# APM32F445 register map
File version: 1.0
CPU: CM4 r0p1, little endian, MPU, FPU, 4 interrupt priority bits
Registers are 32-bit, read-write, reset 0x0 unless marked. A register's access mark holds for its fields unless they carry their own. Offsets are from the block's base; [hi:lo] are bit positions; {n}, {i} and the like mark numbered series; 'fields as' and 'values as' point back to an identical list.

## PMA — Port Management
Base 0x40049000
Same registers: PMB 0x4004A000, PMC 0x4004B000, PMD 0x4004C000, PME 0x4004D000
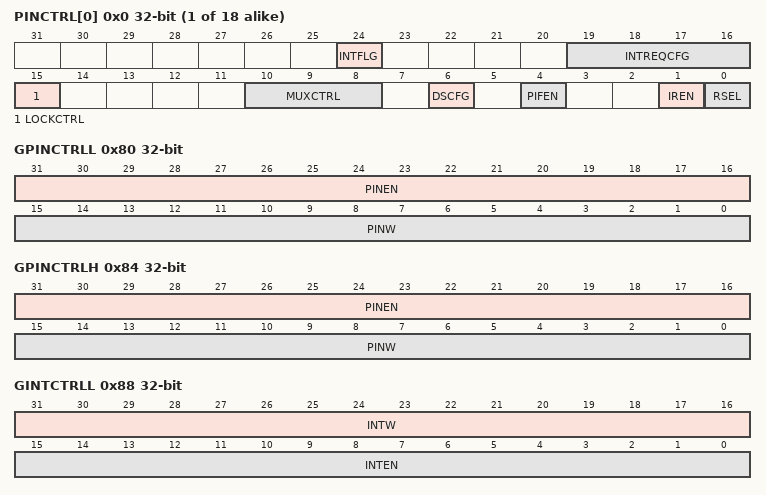
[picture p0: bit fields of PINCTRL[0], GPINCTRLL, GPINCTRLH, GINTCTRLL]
{0x0+4i} PINCTRL[{i}] (i=0..17) — Pin Control Register x
  [24] INTFLG — Interrupt Flag
  [19:16] INTREQCFG — Interrupt Request Configure
  [15] LOCKCTRL — Control Register Lock
  [10:8] MUXCTRL — Pin Mux Control
  [6] DSCFG — Drive Strength Configure
  [4] PIFEN — Passive Input Filter Enable
  [1] IREN — Internal Pullup or Pulldown Resistor Enable
  [0] RSEL — Pullup or Pulldown Resistor Select
0x80 GPINCTRLL wo — Global Pin Control Low Register
  [31:16] PINEN — Global Pin Enable
    0=Corresponding Pin Control Register is not updated with the value in GPWD; 1=Corresponding Pin Control Register is updated with the value in GPWD
  [15:0] PINW — Global Pin Value Write
0x84 GPINCTRLH wo — Global Pin Control High Register
  [31:16] PINEN — Global Interrupt Enable
    values as GPINCTRLL.PINEN
  [15:0] PINW — Global Pin Value Write
0x88 GINTCTRLL wo — Global Interrupt Control Low Register
  [31:16] INTW — Global Interrupt Value Write
  [15:0] INTEN — Global Interrupt Enable
    values as GPINCTRLL.PINEN
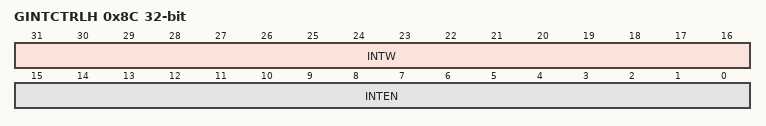
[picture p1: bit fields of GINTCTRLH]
0x8C GINTCTRLH wo — Global Interrupt Control High Register
  fields as GINTCTRLL
0xA0 INTSTS — Interrupt Status Register
  [31:0] INTFLG — Interrupt Flag
    0=Configured interrupt is not detected; 1=Configured interrupt is detected. If the pin is configured to generate a DMA request, then the corresponding flag will be cleared automatically at the completion of the requested DMA transfer. Otherwise, the flag remains set until a logic 1 is written to the flag. If the pin is configured for a level sensitive interrupt and the pin remains asserted, then the flag is set again immediately after it is cleared.
0xC0 DFEN — Digital Filter Enable Register
  [31:0] DOFEN — Digital Output Filter Enable
    0=Digital filter is disabled on the corresponding pin and output of the digital filter is reset to zero; 1=Digital filter is enabled on the corresponding pin, if the pin is configured as a digital input
0xC4 DFCLKS — Digital Filter Clock Source Register
  [0] DFCLKS — Digital Filter Clock Source
    0=Digital filters are clocked by the bus clock; 1=Digital filters are clocked by the LPO clock
0xC8 DFWID — Digital Filter Length Register
  [4:0] DFWID — Digital Filter Width

## WDT — Software Watchdog Timer
Base 0x40052000
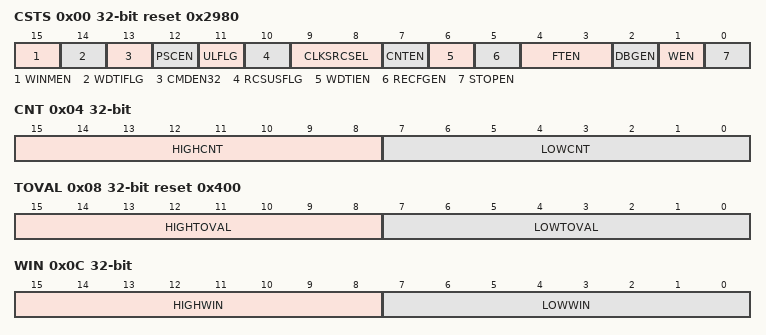
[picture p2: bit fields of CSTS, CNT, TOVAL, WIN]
0x00 CSTS reset 0x2980 — Control and Status Register
  [15] WINMEN — Window Mode Enable
    0=Window mode disabled; 1=Window mode enabled
  [14] WDTIFLG — Watchdog Interrupt Flag
    0=No interrupt occurred; 1=An interrupt occurred
  [13] CMDEN32 — 32-bit Refresh / Unlock Command Write Word Enable
    0=Disables support for 32-bit refresh/unlock command write words. Only 16-bit or 8-bit is supported.; 1=Enables support for 32-bit refresh/unlock command write words. 16-bit or 8-bit is NOT supported.
  [12] PSCEN — Prescaler Enable
    0=256 prescaler disabled; 1=256 prescaler enabled
  [11] ULFLG ro — Unlock Flag
    0=WDT is locked; 1=WDT is unlocked
  [10] RCSUSFLG ro — Reconfigure Success Flag
    0=Reconfiguring WDT; 1=Reconfiguration is successful
  [9:8] CLKSRCSEL — Watchdog Clock Source Select
    0=Bus clock; 1=LPO clock; 2=INTCLK (internal clock); 3=ERCLK (external reference clock)
  [7] CNTEN — Watchdog Count Enable
    0=Watchdog disabled; 1=Watchdog enabled
  [6] WDTIEN — Watchdog Interrupt Enable
    0=Watchdog interrupts are disabled. Watchdog resets are not delayed.; 1=Watchdog interrupts are enabled. Watchdog resets are delayed by 8'd128 bus clocks from the interrupt vector fetch.
  [5] RECFGEN — Watchdog Reconfigure Enable
    0=Updates not allowed. After the initial configuration, the watchdog cannot be later modified without forcing a reset.; 1=Updates allowed. Software can modify the watchdog configuration registers within 8'd128 bus clocks after performing the unlock write sequence.
  [4:3] FTEN — Fast Test Enable
    0=Watchdog test mode disabled; 1=Watchdog user mode enabled. (Watchdog test mode disabled.) After testing the watchdog, software should use this setting to indicate that the watchdog is functioning normally in user mode.; 2=Watchdog test mode enabled, only the low byte is used. CNT[LOWCNT] is compared with TOVAL[LOWTOVAL].; 3=Watchdog test mode enabled, only the high byte is used. CNT[HIGHCNT] is compared with TOVAL[HIGHTOVAL].
  [2] DBGEN — Watchdog in Debug Mode Enable
    0=Watchdog disabled in chip debug mode; 1=Watchdog enabled in chip debug mode
  [1] WEN — Watchdog in Wait Mode Enable
    0=Watchdog disabled in chip wait mode; 1=Watchdog enabled in chip wait mode
  [0] STOPEN — Watchdog in Stop Mode Enable
    0=Watchdog disabled in chip stop mode; 1=Watchdog enabled in chip stop mode
0x04 CNT — Counter Register
  [15:8] HIGHCNT — High Byte of Counter
  [7:0] LOWCNT — Low Byte of Counter
0x08 TOVAL reset 0x400 — Timeout Value Register
  [15:8] HIGHTOVAL — High Byte of Timeout Value
  [7:0] LOWTOVAL — Low Byte of Timeout Value
0x0C WIN — Window Register
  [15:8] HIGHWIN — High Byte of Window
  [7:0] LOWWIN — Low Byte of Window
